# nrf9120_MLM1 register map
Vendor: Nordic Semiconductor; Series: nrf91; File version: 1
CPU: CM4 r0p1, little endian, MPU, FPU, 3 interrupt priority bits
Registers are 32-bit, read-write, reset 0x0 unless marked. A register's access mark holds for its fields unless they carry their own. Offsets are from the block's base; [hi:lo] are bit positions; lines under a group give offsets from that group; {n}, {i} and the like mark numbered series; 'fields as' and 'values as' point back to an identical list.

## TAD — Trace and debug control
Base 0xE0080000
0x500 ENABLE — Enable debug domain and aquire selected GPIOs
  [0] ENABLE
    0=DISABLED (Disable debug domain and release selected GPIOs); 1=ENABLED (Enable debug domain and aquire selected GPIOs)
0x504 PSEL group — Unspecified
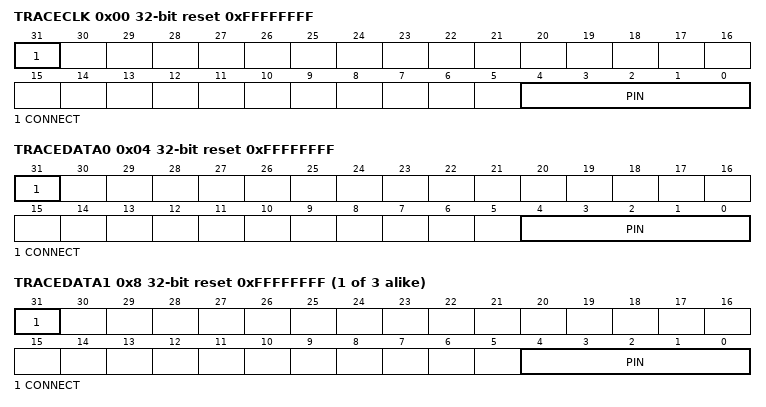
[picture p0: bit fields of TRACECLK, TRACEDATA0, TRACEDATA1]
  0x00 TRACECLK reset 0xFFFFFFFF — Pin number configuration for TRACECLK
    [31] CONNECT — Connection
      1=Disconnected; 0=Connected
    [4:0] PIN — Pin number
  0x04 TRACEDATA0 reset 0xFFFFFFFF — Pin number configuration for TRACEDATA[0] and SWO
    fields as PSEL.TRACECLK
  {0x4+4j} TRACEDATA{j} reset 0xFFFFFFFF (j=1..3) — Pin number configuration for TRACEDATA[{j}]
    fields as PSEL.TRACECLK
0x518 TRACEPORTSPEED — Clocking options for the Trace Port debug interface
  [1:0] TRACEPORTSPEED — Speed of Trace Port clock. Note that the TRACECLK pin will output this clock divided by two.
    0=32 MHz Trace Port clock (TRACECLK = 16 MHz); 1=16 MHz Trace Port clock (TRACECLK = 8 MHz); 2=8 MHz Trace Port clock (TRACECLK = 4 MHz); 3=4 MHz Trace Port clock (TRACECLK = 2 MHz)

## UICR — User Information Configuration Registers
Base 0x00FF8000
0x00 APPROTECT reset 0xFFFFFFFF — Access port protection
  [7:0] PALL — Blocks debugger read/write access to all CPU registers and memory mapped addresses except for the Control Access Port registers.
    255=Disabled; 0=Enabled
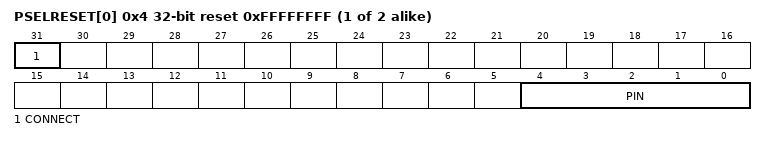
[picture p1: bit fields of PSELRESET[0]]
{0x4+4i} PSELRESET[{i}] (i=0..1) reset 0xFFFFFFFF — Description collection[0]: Mapping of the nRESET function (see POWER chapter for details)
  [31] CONNECT — Connection
    1=Disconnected; 0=Connected
  [4:0] PIN — GPIO number P0.n onto which Reset is exposed
0x0C EXTSUPPLY reset 0xFFFFFFFF — Enable external circuitry to be supplied from VDD pin. Applicable in "High voltage mode" only.
  [0] EXTSUPPLY — Enable external circuitry to be supplied from VDD pin (output of REG0 stage).
    0=Disabled (No current can be drawn from the VDD pin.); 1=Enabled (It is allowed to supply external circuitry from the VDD pin.)
0x10 REGOUT0 reset 0xFFFFFFFF — GPIO reference voltage / external output supply voltage in "High voltage mode".
  [2:0] VOUT — Output voltage from of REG0 regulator stage. The maximum output voltage from this stage is given as VDDH - VEXDIF.
    0=1V8 (1.8 V); 1=2V1 (2.1 V); 2=2V4 (2.4 V); 3=2V7 (2.7 V); 4=3V0 (3.0 V); 5=3V3 (3.3 V); 7=DEFAULT (Default voltage: 1.8 V)
0x14 NFCPINS reset 0xFFFFFFFF — Setting of pins dedicated to NFC functionality: NFC antenna or GPIO
  [0] PROTECT — Setting of pins dedicated to NFC functionality
    0=Disabled (Operation as GPIO pins. Same protection as normal GPIO pins); 1=NFC (Operation as NFC antenna pins. Configures the protection for NFC operation)
0x18 XOSC32M reset 0xFFFFFF0F — Oscillator Control
  [4:0] CTRL — Setting of pins dedicated to NFC functionality
{0x100+4i} NRFHW[{i}] (i=0..31) reset 0xFFFFFFFF — Description collection[0]: Reserved for Nordic hardware design
  [31:0] NRFHW — Reserved for Nordic hardware design
{0x200+4i} NRFFW[{i}] (i=0..31) reset 0xFFFFFFFF — Description collection[0]: Reserved for Nordic firmware design
  [31:0] NRFFW — Reserved for Nordic firmware design
{0x300+4i} CUSTOMER[{i}] (i=0..31) reset 0xFFFFFFFF — Description collection[0]: Reserved for customer
  [31:0] CUSTOMER — Reserved for customer

## PMU_OSCILLATORS
Base 0x40000000; alternate view of PMU_REGULATORS

## RADIOLTE — LTE-M Radio
Base 0x40000000; alternate view of PMU_REGULATORS

## AMLI — AHB Multi-Layer Interface
Base 0x40000000; alternate view of PMU_REGULATORS
0xE00 RAMPRI group — RAM configurable priority configuration structure
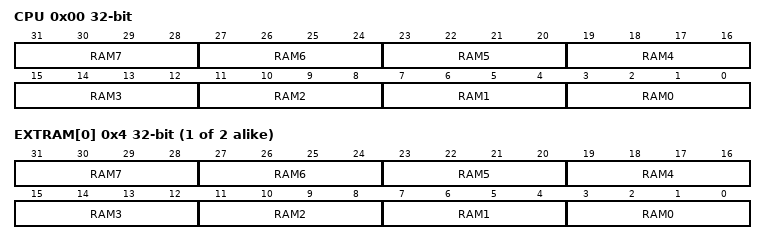
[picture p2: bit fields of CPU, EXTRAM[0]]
  0x00 CPU — AHB bus master priority register for CPU
    [all] fields
      {v}=Pri{v} (Priority {v}) (v=0..15)
    [4n+3:4n] RAM{n} (n=0..7) — Priority register for RAM AHB slave {n}
  {0x4+4j} EXTRAM[{j}] (j=0..1) — Description collection[0]: AHB bus master priority register for external RAM slave port (EXTRAMs)
    fields as RAMPRI.CPU
